# MSS_DMM2 register map
Vendor: Texas Instruments
Peripheral module from a debugger description file (folder radar).
Registers are 32-bit, read-write, no defined reset value unless marked. A register's access mark holds for its fields unless they carry their own. Offsets are as the file gives them; lines under a group give offsets from that group; [hi:lo] are bit positions; {n}, {i} and the like mark numbered series; 'fields as' and 'values as' point back to an identical list; <NAME> marks a mode.

## MSS_DMM2
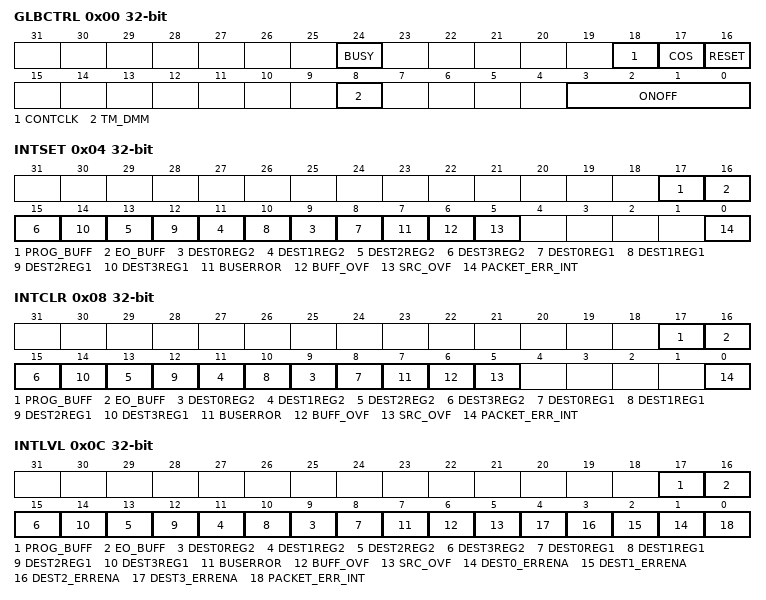
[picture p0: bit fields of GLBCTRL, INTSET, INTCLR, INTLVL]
0x00 GLBCTRL — Sets the global configuration of the module
  [24] BUSY — BUSY User and privilege mode (read): 0 = the DMM does not currently receive data and has no data in its internal buffers, which need to be transfered. 1 = the module is currently receiving data, or has data in its internal buffers Privilege mode (write): Writes have no effect
  [18] CONTCLK — CONTCLK. Continous RTPCLK output User and privilege mode (read): 0 = RTPCLK will be suspended between two packets 1 = free running RTPCLK Privilege mode (write): 0 = suspend RTPCLK between packets 1 = enable free running clock between packets
  [17] COS — COS. Continue On Suspend Influences behaviour of module while in suspend mode. In all cases the corresponding interrupt will be set. User and privilege mode (read): 0 = before entering suspend mode, the ongoing reception (if started 1 HCLK cycle before SUSPEND goes high) of a packet will be finished and the value will be written to the destination. 2 HCLK cycles after SUSPEND goes low, the reception of packets is enabled again. 1 = continue receiving packets and update destination, while in suspend mode Privilege mode (write): 0 = disable data reception while in suspend mode 1 = enable data reception while in suspend mode
  [16] RESET — RESET This bit resets the statemachine and the registers to its reset value, except the RESET bit itself. It has to be cleared by writing to it. User and privilege mode (read): 0 = no reset of DMM module 1 = reset of DMM module Privilege mode (write): 0 = no reset of DMM module 1 = reset DMM module to its reset state
  [8] TM_DMM — TM_DMM: Packet Format If this bit is set, the DMM module assumes to receive packets by the Direct Data Mode. User and privilege mode (read): 0 = the DMM module assumes packets in Trace Mode definition 1 = the DMM module assumes packets in Direct Data Mode definition Privilege mode (write): 0 = enable Trace Mode 1 = enable Direct Data Mode
  [3:0] ONOFF — ON/OFF User and privilege mode (read): 1010 = the DMM module receives data and writes it to the buffer all other = the DMM module does not receive data Privilege mode (write): 1010 = enable receive/write operations. Packets will be received 1 HCLK cycle after enabling the module all other = disable receive/write operations. Packets in reception will be finished. NOTE: It is recommended to write 0101 to avoid having a soft error inadvertently enabling the module. NOTE: Registers which affect the operation of the module, should be only programmed when the BUSY bit is 0 and the ON/OFF bits are not 1010. NOTE: If the module was turned off (ON/OFF != 1010) and then turned on (ON/OFF = 1010) again, it is recommended to perform a reset (RESET = 1) of the module before switching it on. This avoids that the state machine is held in an unrecoverable state.
0x04 INTSET — Enables interrupts
  [17] PROG_BUFF — PROG_BUFF: Programmable Buffer Interrupt Set This enables the interrupt generation in case the buffer pointer equals the programmed value in the DMMINTPT register. User and privilege mode (read): 0 = no interrupt will be generated 1 = an interrupt will be generated Privilege mode (write): 0 = no influence on bit 1 = enable interrupt (sets corresponding bit in DMMINTCLR)
  [16] EO_BUFF — EO_BUFF: End of Buffer Interrupt Set This enables the interrupt generation in case data was written to the last entry in the buffer and the pointer wrapped around. User and privilege mode (read): 0 = no interrupt will be generated 1 = an interrupt will be generated Privilege mode (write): 0 = no influence on bit 1 = enable interrupt (sets corresponding bit in DMMINTCLR)
  [2n+9] DEST{n}REG2 (n=0..3) — DEST{n}REG2: Destination {n} Region 2 Interrupt Set This enables the interrupt generation in case data was accessed at the startaddress of Destination {n} Region 2. User and privilege mode (read): 0 = no interrupt will be generated 1 = an interrupt will be generated Privilege mode (write): 0 = no influence on bit 1 = enable interrupt (sets corresponding bit in DMMINTCLR)
  [2n+8] DEST{n}REG1 (n=0..3) — DEST{n}REG1: Destination {n} Region 1 Interrupt Set This enables the interrupt generation in case data was accessed at the startaddress of Destination {n} Region 1. User and privilege mode (read): 0 = no interrupt will be generated 1 = an interrupt will be generated Privilege mode (write): 0 = no influence on bit 1 = enable interrupt (sets corresponding bit in DMMINTCLR)
  [7] BUSERROR — BUSERROR: BMM Bus Error Response User and privilege mode (read): 0 = no interrupt will be generated 1 = an interrupt will be generated on BMM HRESP = Error Privilege mode (write): 0 = no influence on bit 1 = enable interrupt when BMM HRESP = Error
  [6] BUFF_OVF — BUFF_OVF: Write Buffer Overflow Interrupt Set This enables the interrupt generation in case new data is received, while the previous data is still in the deserializer. User and privilege mode (read): 0 = no interrupt will be generated 1 = an interrupt will be generated Privilege mode (write): 0 = no influence on bit 1 = enable interrupt (sets corresponding bit in DMMINTCLR)
  [5] SRC_OVF — SRC_OVF: Source Overflow Interrupt Set This enables the interrupt generation in case a overflow was denoted in the STAT bits of the received packet. User and privilege mode (read): 0 = no interrupt will be generated 1 = an interrupt will be generated Privilege mode (write): 0 = no influence on bit 1 = enable interrupt (sets corresponding bit in DMMINTCLR)
  [0] PACKET_ERR_INT — PACKET_ERR_INT: Packet Error Interrupt Set This enables the interrupt generation in case of an error condition. Either the number of bits received on a Trace Mode packet doesn’t correspond to the size specified in the SIZE field or the number of bits received on a Direct Data Mode packet doesn’t equal the number of programmed bits in DMMGLBCTRL[10:9]. User and privilege mode (read): 0 = no interrupt will be generated 1 = an interrupt will be generated in case of an overflow or packet error. Privilege mode (write): 0 = no influence on bit 1 = enable interrupt (sets corresponding bit in DMMINTCLR)
0x08 INTCLR — Disables interrupts
  [17] PROG_BUFF — PROG_BUFF: Programmable Buffer Interrupt Clear This disables the interrupt generation in case the buffer pointer equals the programmed value in the DMMINTPT register. User and privilege mode (read): 0 = no interrupt will be generated 1 = an interrupt will be generated Privilege mode (write): 0 = no influence on bit 1 = disable interrupt (clears corresponding bit in DMMINTSET)
  [16] EO_BUFF — EO_BUFF: End of Buffer Interrupt Clear This disables the interrupt generation in case data was written to the last entry in the buffer and the pointer wrapped around. User and privilege mode (read): 0 = no interrupt will be generated 1 = an interrupt will be generated Privilege mode (write): 0 = no influence on bit 1 = disable interrupt (clears corresponding bit in DMMINTSET)
  [2n+9] DEST{n}REG2 (n=0..3) — DEST{n}REG2: Destination {n} Region 2 Interrupt Clear This disables the interrupt generation in case data was accessed at the startaddress of Destination {n} Region 2. User and privilege mode (read): 0 = no interrupt will be generated 1 = an interrupt will be generated Privilege mode (write): 0 = no influence on bit 1 = disable interrupt (clears corresponding bit in DMMINTSET)
  [2n+8] DEST{n}REG1 (n=0..3) — DEST{n}REG1: Destination {n} Region 1 Interrupt Clear This disables the interrupt generation in case data was accessed at the startaddress of Destination {n} Region 1. User and privilege mode (read): 0 = no interrupt will be generated 1 = an interrupt will be generated Privilege mode (write): 0 = no influence on bit 1 = disable interrupt (clears corresponding bit in DMMINTSET)
  [7] BUSERROR — BUSERROR: BMM Bus Error Response User and privilege mode (read): 0 = no interrupt will be generated 1 = an interrupt will be generated on BMM HRESP = Error Privilege mode (write): 0 = no influence on bit 1 = disable interrupt on BMM HRESP = Error
  [6] BUFF_OVF — BUFF_OVF: Write Buffer Overflow Interrupt Clear This disables the interrupt generation in case new data is received, while the previous data is still in the deserializer.. User and privilege mode (read): 0 = no interrupt will be generated 1 = an interrupt will be generated Privilege mode (write): 0 = no influence on bit 1 = disable interrupt (clears corresponding bit in DMMINTSET)
  [5] SRC_OVF — SRC_OVF: Source Overflow Interrupt Clear This disables the interrupt generation in case a overflow was denoted in the STAT bits of the received packet. User and privilege mode (read): 0 = no interrupt will be generated 1 = an interrupt will be generated Privilege mode (write): 0 = no influence on bit 1 = disable interrupt (clears corresponding bit in DMMINTSET)
  [0] PACKET_ERR_INT — PACKET_ERR_INT: Packet Error Interrupt Clear This disables the interrupt generation in case of an error condition. Either the number of bits received on a Trace Mode packet doesn’t correspond to the size specified in the SIZE field or the number of bits received on a Direct Data Mode packet doesn’t equal the number of programmed bits in DMMGLBCTRL[10:9]. User and privilege mode (read): 0 = no interrupt will be generated 1 = an interrupt will be generated in case of an overflow or packet error. Privilege mode (write): 0 = no influence on bit 1 = disable interrupt (clears corresponding bit in DMMINTSET)
0x0C INTLVL — Selects high or low priority interrupt level
  [17] PROG_BUFF — PROG_BUFF: Programmable Buffer Interrupt Level User and privilege mode (read): 0 = interrupt mapped to level 0 1 = interrupt mapped to level 1 Privilege mode (write): 0 = interrupt will be mapped to level 0 1 = interrupt will be mapped to level 1
  [16] EO_BUFF — EO_BUFF: End of Buffer Interrupt Level User and privilege mode (read): 0 = interrupt mapped to level 0 1 = interrupt mapped to level 1 Privilege mode (write): 0 = interrupt will be mapped to level 0 1 = interrupt will be mapped to level 1
  [2n+9] DEST{n}REG2 (n=0..3) — DEST{n}REG2: Destination {n} Region 2 Interrupt Level User and privilege mode (read): 0 = interrupt mapped to level 0 1 = interrupt mapped to level 1 Privilege mode (write): 0 = interrupt will be mapped to level 0 1 = interrupt will be mapped to level 1
  [2n+8] DEST{n}REG1 (n=0..3) — DEST{n}REG1: Destination {n} Region 1 Interrupt Level User and privilege mode (read): 0 = interrupt mapped to level 0 1 = interrupt mapped to level 1 Privilege mode (write): 0 = interrupt will be mapped to level 0 1 = interrupt will be mapped to level 1
  [7] BUSERROR — BUSERROR: BMM Bus Error Response User and privilege mode (read): 0 = interrupt mapped to level 0 1 = interrupt mapped to level 1 Privilege mode (write): 0 = interrupt will be mapped to level 0 1 = interrupt will be mapped to level 1
  [6] BUFF_OVF — BUFF_OVF: Write Buffer Overflow Interrupt Level User and privilege mode (read): 0 = interrupt mapped to level 0 1 = interrupt mapped to level 1 Privilege mode (write): 0 = interrupt will be mapped to level 0 1 = interrupt will be mapped to level 1
  [5] SRC_OVF — SRC_OVF: Source Overflow Interrupt Level User and privilege mode (read): 0 = interrupt mapped to level 0 1 = interrupt mapped to level 1 Privilege mode (write): 0 = interrupt will be mapped to level 0 1 = interrupt will be mapped to level 1
  [n+1] DEST{n}_ERRENA (n=0..3) — DEST{n}_ERRENA: Destination {n} Error Interrupt Level User and privilege mode (read): 0 = interrupt mapped to level 0 1 = interrupt mapped to level 1 Privilege mode (write): 0 = interrupt will be mapped to level 0 1 = interrupt will be mapped to level 1
  [0] PACKET_ERR_INT — PACKET_ERR_INT: Packet Error Interrupt Level User and privilege mode (read): 0 = interrupt mapped to level 0 1 = interrupt mapped to level 1 Privilege mode (write): 0 = interrupt will be mapped to level 0 1 = interrupt will be mapped to level 1
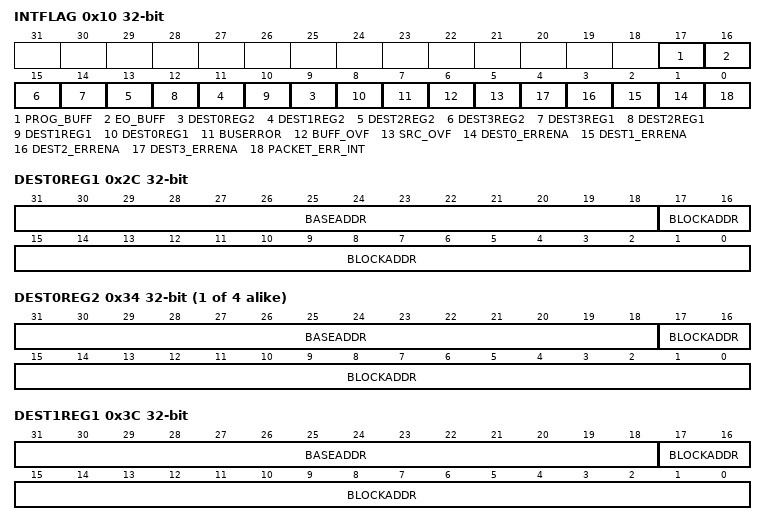
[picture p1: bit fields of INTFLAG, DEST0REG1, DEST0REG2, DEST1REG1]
0x10 INTFLAG — Interrupt Flags
  [17] PROG_BUFF — PROG_BUFF: Programmable Buffer Interrupt Flag User and privilege mode (read): 0 = no interrupt occured 1 = interrupt occured Privilege mode (write): 0 = no influence on bit 1 = bit will be cleared
  [16] EO_BUFF — EO_BUFF: End of Buffer Interrupt Flag User and privilege mode (read): 0 = no interrupt occured 1 = interrupt occured Privilege mode (write): 0 = no influence on bit 1 = bit will be cleared
  [2n+9] DEST{n}REG2 (n=0..3) — DEST{n}REG2: Destination {n} Region 2 Interrupt Flag User and privilege mode (read): 0 = no interrupt occured 1 = interrupt occured Privilege mode (write): 0 = no influence on bit 1 = bit will be cleared
  [14] DEST3REG1 — DEST3REG1: Destination 3 Region 1 Interrupt Flag User and privilege mode (read): 0 = no interrupt occured 1 = interrupt occured Privilege mode (write): 0 = no influence on bit 1 = bit will be cleared
  [12] DEST2REG1 — DEST2REG1: Destination 2 Region 1 Interrupt Flag User and privilege mode (read): 0 = no interrupt occured 1 = interrupt occured Privilege mode (write): 0 = no influence on bit 1 = bit will be cleared
  [10] DEST1REG1 — DEST1REG1: Destination 1 Region 1 Interrupt Flag User and privilege mode (read): 0 = no interrupt occured 1 = interrupt occured Privilege mode (write): 0 = no influence on bit 1 = bit will be cleared
  [8] DEST0REG1 — DEST0REG1: Destination 0 Region 1 Interrupt Flag User and privilege mode (read): 0 = no interrupt occurred 1 = interrupt occured Privilege mode (write): 0 = no influence on bit 1 = bit will be cleared
  [7] BUSERROR — BUSERROR: BMM Bus Error Response This bit is set when the BMM HRESP = Error. User and privilege mode (read): 0 = no interrupt occured 1 = interrupt occured Privilege mode (write): 0 = no influence on bit 1 = bit will be cleared
  [6] BUFF_OVF — BUFF_OVF: Write Buffer Overflow Interrupt Flag User and privilege mode (read): 0 = no interrupt occured 1 = interrupt occured Privilege mode (write): 0 = no influence on bit 1 = bit will be cleared
  [5] SRC_OVF — SRC_OVF: Source Overflow Interrupt Flag User and privilege mode (read): 0 = no interrupt occured 1 = interrupt occured Privilege mode (write): 0 = no influence on bit 1 = bit will be cleared
  [n+1] DEST{n}_ERRENA (n=0..3) — DEST{n}_ERRENA: Destination {n} Error Interrupt Flag User and privilege mode (read): 0 = no interrupt occured 1 = interrupt occured Privilege mode (write): 0 = no influence on bit 1 = bit will be cleared
  [0] PACKET_ERR_INT — PACKET_ERR_INT: Packet Error Interrupt Flag User and privilege mode (read): 0 = no interrupt occured 1 = interrupt occured Privilege mode (write): 0 = no influence on bit 1 = bit will be cleared
0x1C DDMDEST — Configuration of Buffer for Direct Data Mode
  [31:0] STARTADDR — STARTADDR[31:0] These bits define the starting address of the buffer. The starting address has to be a multiple of the blocksize chosen in DMMDDMBL. User and privilege mode (read): current start address Privilege mode (write): sets start address to value written
0x24 DDMPT — Pointer to the last written entry in the buffer
  [14:0] POINTER — POINTER These bits hold the pointer to the next entry to be written in the buffer. The pointer points to the byte aligned address. If in 16-bit DDM mode, bit 0 will be discarded. If in 32-bit DDM mode, bit 0 and 1 will be discarded. User and privilege mode (read): next pointer entry Privilege mode (write): writes have no effect
0x28 INTPT — Programmable Interrupt Pointer
  [14:0] INTPT — INTPT: Interrupt Pointer When the buffer pointer (DMMDDMPT) matches the programmed value in DMMINTPT and the PROG_BUF interrupt is set, a interrupt is generated. User and privilege mode (read): current interrupt pointer Privilege mode (write): new interrupt pointer
0x2C DEST0REG1 — Defines Region 1 for Destination 0
  [31:18] BASEADDR — BASEADDR[31:18] These bits define the base address of the 256kB region where the buffer is located. User and privilege mode (read): current start address Privilege mode (write): sets base address to value written
  [17:0] BLOCKADDR — BLOCKADDR[17:0] These bits define the starting address of the buffer in the 256kB page. The starting address has to be a multiple of the blocksize chosen in DMMDEST0BL1. User and privilege mode (read): current start address Privilege mode (write): sets start address to value written
{0x34+0x10*i} DEST{i}REG2 (i=0..3) — Defines Region 2 for Destination {i}
  [31:18] BASEADDR — BASEADDR[31:18] These bits define the base address of the 256kB region where the buffer is located. User and privilege mode (read): current start address Privilege mode (write): sets base address to value written
  [17:0] BLOCKADDR — BLOCKADDR[17:0] These bits define the starting address of the buffer in the 256kB page. The starting address has to be a multiple of the blocksize chosen in DMMDEST{i}BL2. User and privilege mode (read): current start address Privilege mode (write): sets start address to value written
0x3C DEST1REG1 — Defines Region 1 for Destination1
  [31:18] BASEADDR — BASEADDR[31:18] These bits define the base address of the 256kB region where the buffer is located. User and privilege mode (read): current start address Privilege mode (write): sets base address to value written
  [17:0] BLOCKADDR — BLOCKADDR[17:0] These bits define the starting address of the buffer in the 256kB page. The starting address has to be a multiple of the blocksize chosen in DMMDEST1BL1. User and privilege mode (read): current start address Privilege mode (write): sets start address to value written
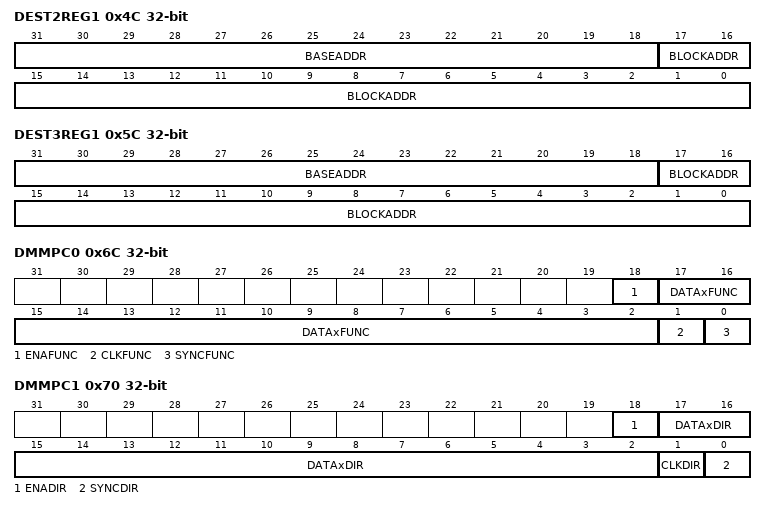
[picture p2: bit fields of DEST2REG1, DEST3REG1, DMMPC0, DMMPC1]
0x4C DEST2REG1 — Defines Region 1 for Destination 2
  [31:18] BASEADDR — BASEADDR[31:18] These bits define the base address of the 256kB region where the buffer is located. User and privilege mode (read): current start address Privilege mode (write): sets base address to value written
  [17:0] BLOCKADDR — BLOCKADDR[17:0] These bits define the starting address of the buffer in the 256kB page. The starting address has to be a multiple of the blocksize chosen in DMMDEST2BL1. User and privilege mode (read): current start address Privilege mode (write): sets start address to value written
0x5C DEST3REG1 — Defines Region 1 for Destination 3
  [31:18] BASEADDR — BASEADDR[31:18] These bits define the base address of the 256kB region where the buffer is located. User and privilege mode (read): current start address Privilege mode (write): sets base address to value written
  [17:0] BLOCKADDR — BLOCKADDR[17:0] These bits define the starting address of the buffer in the 256kB page. The starting address has to be a multiple of the blocksize chosen in DMMDEST3BL1. User and privilege mode (read): current start address Privilege mode (write): sets start address to value written
0x6C DMMPC0 — Defines functional or GIO mode of pins
  [18] ENAFUNC — ENAFUNC: Functional mode of DMMENA pin This bit defines whether the pin is used in functional mode or in GIO mode User and privilege mode (read): 0 = Pin is used in GIO mode 1 = Pin is used in Functional mode Privilege mode (write): 0 = Pin is used in GIO mode 1 = Pin is used in Functional mode
  [17:2] DATAxFUNC — DATAxFUNC: Functional mode of DMMDATA[x] pin This bit defines whether the pin is used in functional mode or in GIO mode User and privilege mode (read): 0 = Pin is used in GIO mode 1 = Pin is used in FunctionaPrivilege mode (write): 0 = Pin is used in GIO mode 1 = Pin is used in Functional model mode
  [1] CLKFUNC — CLKFUNC: Functional mode of DMMCLK pin This bit defines whether the pin is used in functional mode or in GIO mode User and privilege mode (read): 0 = Pin is used in GIO mode 1 = Pin is used in Functional mode Privilege mode (write): 0 = Pin is used in GIO mode 1 = Pin is used in Functional mode
  [0] SYNCFUNC — SYNCFUNC: Functional mode of DMMSYNC pin This bit defines whether the pin is used in functional mode or in GIO mode User and privilege mode (read): 0 = Pin is used in GIO mode 1 = Pin is used in Functional mode Privilege mode (write): 0 = Pin is used in GIO mode 1 = Pin is used in Functional mode
0x70 DMMPC1 — Defines direction of pins
  [18] ENADIR — ENADIR: Direction of DMMENA pin This bit defines whether the pin is used as input or output in GIO mode User and privilege mode (read): 0 = Pin is used as input 1 = Pin is used as output Privilege mode (write): 0 = Pin is set to input 1 = Pin is set to output
  [17:2] DATAxDIR — DATAxDIR: Direction of DMMDATA[x] pin This bit defines whether the pin is used as input or output in GIO mode User and privilege mode (read): 0 = Pin is used as input 1 = Pin is used as output Privilege mode (write): 0 = Pin is set to input 1 = Pin is set to output
  [1] CLKDIR — CLKDIR: Direction of DMMCLK pin This bit defines whether the pin is used as input or output in GIO mode User and privilege mode (read): 0 = Pin is used as input 1 = Pin is used as output Privilege mode (write): 0 = Pin is set to input 1 = Pin is set to output
  [0] SYNCDIR — SYNCDIR: Direction of DMMSYNC pin This bit defines whether the pin is used as input or output in GIO mode User and privilege mode (read): 0 = Pin is used as input 1 = Pin is used as output Privilege mode (write): 0 = Pin is set to input 1 = Pin is set to output
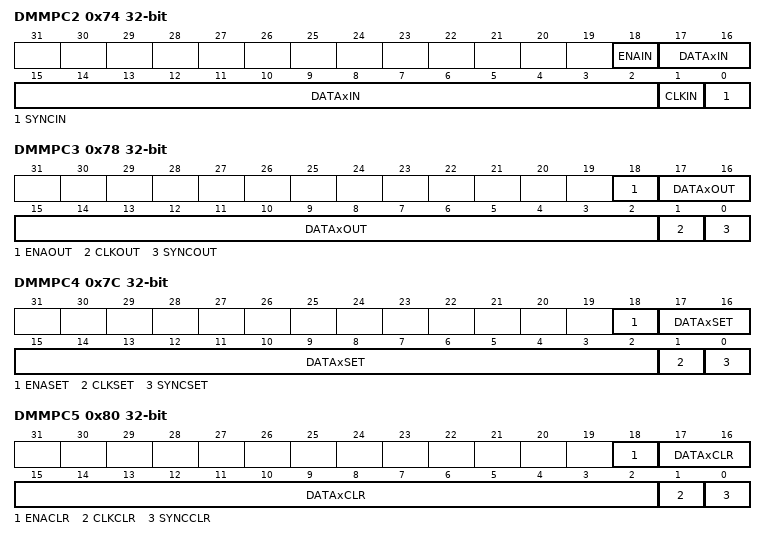
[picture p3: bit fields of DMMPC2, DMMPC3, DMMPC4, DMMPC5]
0x74 DMMPC2 — Input level of pins
  [18] ENAIN — ENAIN: DMMENA input This bit reflects the state of the pin in all modes User and privilege mode (read): 0 = Logic low (input voltage is VIL or lower) 1 = Logic high (input voltage is VIH or higher) Privilege mode (write): Writes to this bit have no effect.
  [17:2] DATAxIN — DATAxIN: DMMDATA[x] input This bit reflects the state of the pin in all modes User and privilege mode (read): 0 = Logic low (input voltage is VIL or lower) 1 = Logic high (input voltage is VIH or higher) Privilege mode (write): Writes to this bit have no effect
  [1] CLKIN — CLKIN: DMMCLK input This bit reflects the state of the pin in all modes User and privilege mode (read): 0 = Logic low (input voltage is VIL or lower) 1 = Logic high (input voltage is VIH or higher) Privilege mode (write): Writes to this bit have no effect
  [0] SYNCIN — SYNCIN: DMMSYNC input This bit reflects the state of the pin in all modes User and privilege mode (read): 0 = Logic low (input voltage is VIL or lower) 1 = Logic high (input voltage is VIH or higher) Privilege mode (write): Writes to this bit have no effect.
0x78 DMMPC3 — Sets pins to high or low
  [18] ENAOUT — ENAOUT: Output state of DMMENA pin This bit sets the pin to logic low or high level User and privilege mode (read): 0 = Logic low (output voltage is VOL or lower) 1 = Logic high (output voltage is VOH or higher) Privilege mode (write): 0 = Logic low (output voltage is set to VOL or lower) 1 = Logic high (output voltage is set to VOH or higher)
  [17:2] DATAxOUT — DATAxOUT: Output state of DMMDATA[x] pin This bit sets the pin to logic low or high level User and privilege mode (read): 0 = Logic low (output voltage is VOL or lower) 1 = Logic high (output voltage is VOH or higher) Privilege mode (write): 0 = Logic low (output voltage is set to VOL or lower) 1 = Logic high (output voltage is set to VOH or higher)
  [1] CLKOUT — CLKOUT: Output state of DMMCLK pin This bit sets the pin to logic low or high level User and privilege mode (read): 0 = Logic low (output voltage is VOL or lower) 1 = Logic high (output voltage is VOH or higher) Privilege mode (write): 0 = Logic low (output voltage is set to VOL or lower) 1 = Logic high (output voltage is set to VOH or higher)
  [0] SYNCOUT — SYNCOUT: Output state of DMMSYNC pin This bit sets the pin to logic low or high level User and privilege mode (read): 0 = Logic low (output voltage is VOL or lower) 1 = Logic high (output voltage is VOH or higher) Privilege mode (write): 0 = Logic low (output voltage is set to VOL or lower) 1 = Logic high (output voltage is set to VOH or higher)
0x7C DMMPC4 — Sets pins to high
  [18] ENASET — ENASET: Sets output state of DMMENA pin to logic high Value in the ENASET bit sets the data output control register bit to 1 regardless of the current value in the ENAOUT bit User and privilege mode (read): 0 = Logic low (output voltage is VOL or lower) 1 = Logic high (output voltage is VOH or higher) Privilege mode (write): 0 = leaves the pin unchanged 1 = Sets the pin to Logic high (output voltage is set to VOH or higher)
  [17:2] DATAxSET — DATAxSET: Sets output state of DMMDATA[x] pin to logic high Value in the DATAxSET bit sets the data output control register bit to 1 regardless of the current value in the DATAxOUT bit User and privilege mode (read): 0 = Logic low (output voltage is VOL or lower) 1 = Logic high (output voltage is VOH or higher) Privilege mode (write): 0 = leaves the pin unchanged 1 = Sets the pin to Logic high (output voltage is set to VOH or higher)
  [1] CLKSET — CLKSET: Sets output state of DMMCLK pin to logic high Value in the CLKSET bit sets the data output control register bit to 1 regardless of the current value in the CLKOUT bit User and privilege mode (read): 0 = Logic low (output voltage is VOL or lower) 1 = Logic high (output voltage is VOH or higher) Privilege mode (write): 0 = leaves the pin unchanged 1 = Sets the pin to Logic high (output voltage is set to VOH or higher)
  [0] SYNCSET — SYNCSET: Sets output state of DMMSYNC pin logic high Value in the SYNCSET bit sets the data output control register bit to 1 regardless of the current value in the SYNCOUT bit User and privilege mode (read): 0 = Logic low (output voltage is VOL or lower) 1 = Logic high (output voltage is VOH or higher) Privilege mode (write): 0 = leaves the pin unchanged 1 = Sets the pin to Logic high (output voltage is set to VOH or higher)
0x80 DMMPC5 — Sets pins to low
  [18] ENACLR — ENACLR: Sets output state of DMMENA pin to logic low Value in the ENACLR bit clears the data output control register bit to 0 regardless of the current value in the ENAOUT bit User and privilege mode (read): 0 = Logic low (output voltage is VOL or lower) 1 = Logic high (output voltage is VOH or higher) Privilege mode (write): 0 = leaves the pin unchanged 1 = clears the pin to logic low (output voltage is set to VOL or lower)
  [17:2] DATAxCLR — DATAxCLR: Sets output state of DMMDATA[x] pin to logic low Value in the DATAxCLR bit clears the data output control register bit to 0 regardless of the current value in the DATAxOUT bit User and privilege mode (read): 0 = Logic low (output voltage is VOL or lower) 1 = Logic high (output voltage is VOH or higher) Privilege mode (write): 0 = leaves the pin unchanged 1 = clears the pin to logic low (output voltage is set to VOL or lower)
  [1] CLKCLR — CLKCLR: Sets output state of DMMCLK pin to logic low Value in the CLKCLR bit clears the data output control register bit to 0 regardless of the current value in the DATAxOUT bit User and privilege mode (read): 0 = Logic low (output voltage is VOL or lower) 1 = Logic high (output voltage is VOH or higher) Privilege mode (write): 0 = leaves the pin unchanged 1 = clears the pin to logic low (output voltage is set to VOL or lower)
  [0] SYNCCLR — SYNCCLR: Sets output state of DMMSYNC pin to logic low Value in the SYNCCLR bit clears the data output control register bit to 0 regardless of the current value in the DATAxOUT bit User and privilege mode (read): 0 = Logic low (output voltage is VOL or lower) 1 = Logic high (output voltage is VOH or higher) Privilege mode (write): 0 = leaves the pin unchanged 1 = clears the pin to logic low (output voltage is set to VOL or lower)
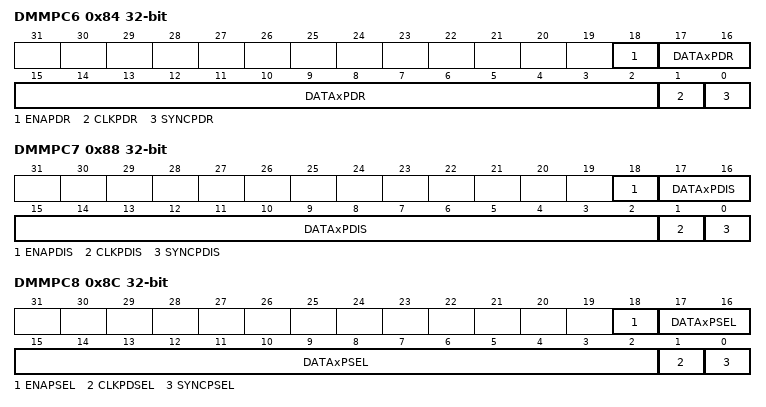
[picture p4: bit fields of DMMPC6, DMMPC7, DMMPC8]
0x84 DMMPC6 — Configures open drain functionality of pin
  [18] ENAPDR — ENAPDR: Open Drain enable Enables open drain functionality on pin if pin is configured as GIO output (DMMPC0.x=0; DMMPC1.x=1). If pin is configured as functional pin (DMMPC0.x=1), the open drain functionality is disabled. User and privilege mode (read): 0 = pin behaves as normal push/pull pin 1 = pin operates in open drain mode Privilege mode (write): 0 = configures pin as push/pull 1 = configures pin as open drain
  [17:2] DATAxPDR — DATAxPDR: Open Drain enable Enables open drain functionality on pin if pin is configured as GIO output (DMMPC0.x=0; DMMPC1.x=1). If pin is configured as functional pin (DMMPC0.x=1), the open drain functionality is disabled. User and privilege mode (read): 0 = pin behaves as normal push/pull pin 1 = pin operates in open drain mode Privilege mode (write): 0 = configures pin as push/pull 1 = configures pin as open drain
  [1] CLKPDR — CLKPDR: Open Drain enable Enables open drain functionality on pin if pin is configured as GIO output (DMMPC0.x=0; DMMPC1.x=1). If pin is configured as functional pin (DMMPC0.x=1), the open drain functionality is disabled. User and privilege mode (read): 0 = pin behaves as normal push/pull pin 1 = pin operates in open drain mode Privilege mode (write): 0 = configures pin as push/pull 1 = configures pin as open drain
  [0] SYNCPDR — SYNCPDR: Open Drain enable Enables open drain functionality on pin if pin is configured as GIO output (DMMPC0.x=0; DMMPC1.x=1). If pin is configured as functional pin (DMMPC0.x=1), the open drain functionality is disabled. User and privilege mode (read): 0 = pin behaves as normal push/pull pin 1 = pin operates in open drain mode Privilege mode (write): 0 = configures pin as push/pull 1 = configures pin as open drain
0x88 DMMPC7 — Enables/Disables pullup/pulldown structure of pin
  [18] ENAPDIS — ENAPDIS: Pull disable Removes internal pullup/pulldown functionality from pin when configured as input pin (DMMPC1.x=0). User and privilege mode (read): 0 = pullup/pulldown functionality enabled 1 = pullup/pulldown functionality disabled Privilege mode (write): 0 = enables pullup/pulldown functionality 1 = disables pullup/pulldown functionality
  [17:2] DATAxPDIS — DATAxPDIS: Pull disable Removes internal pullup/pulldown functionality from pin when configured as input pin (DMMPC1.x=0). User and privilege mode (read): 0 = pullup/pulldown functionality enabled 1 = pullup/pulldown functionality disabled Privilege mode (write): 0 = enables pullup/pulldown functionality 1 = disables pullup/pulldown functionality
  [1] CLKPDIS — CLKPDIS: Pull disable Removes internal pullup/pulldown functionality from pin when configured as input pin (DMMPC1.x=0). User and privilege mode (read): 0 = pullup/pulldown functionality enabled 1 = pullup/pulldown functionality disabled Privilege mode (write): 0 = enables pullup/pulldown functionality 1 = disables pullup/pulldown functionality
  [0] SYNCPDIS — SYNCPDIS: Pull disable Removes internal pullup/pulldown functionality from pin when configured as input pin (DMMPC1.x=0). User and privilege mode (read): 0 = pullup/pulldown functionality enabled 1 = pullup/pulldown functionality disabled Privilege mode (write): 0 = enables pullup/pulldown functionality 1 = disables pullup/pulldown functionality
0x8C DMMPC8 — Enables pullup or pulldown structure of pin
  [18] ENAPSEL — ENAPSEL: Pull select Configures pullup or pulldown functionality if DMMPC7.x=0. User and privilege mode (read): 0 = pulldown functionality enabled 1 = pullup functionality enabled Privilege mode (write): 0 = enables pulldown functionality 1 = enables pullup functionality
  [17:2] DATAxPSEL — DATAxPSEL: Pull select Configures pullup or pulldown functionality if DMMPC7.x=0. User and privilege mode (read): 0 = pulldown functionality enabled 1 = pullup functionality enabled Privilege mode (write): 0 = enables pulldown functionality 1 = enables pullup functionality
  [1] CLKPDSEL — CLKPDSEL: Pull select Configures pullup or pulldown functionality if DMMPC7.x=0. User and privilege mode (read): 0 = pulldown functionality enabled 1 = pullup functionality enabled Privilege mode (write): 0 = enables pulldown functionality 1 = enables pullup functionality
  [0] SYNCPSEL — SYNCPSEL: Pull select Configures pullup or pulldown functionality if DMMPC7.x=0. User and privilege mode (read): 0 = pulldown functionality enabled 1 = pullup functionality enabled Privilege mode (write): 0 = enables pulldown functionality 1 = enables pullup functionality
